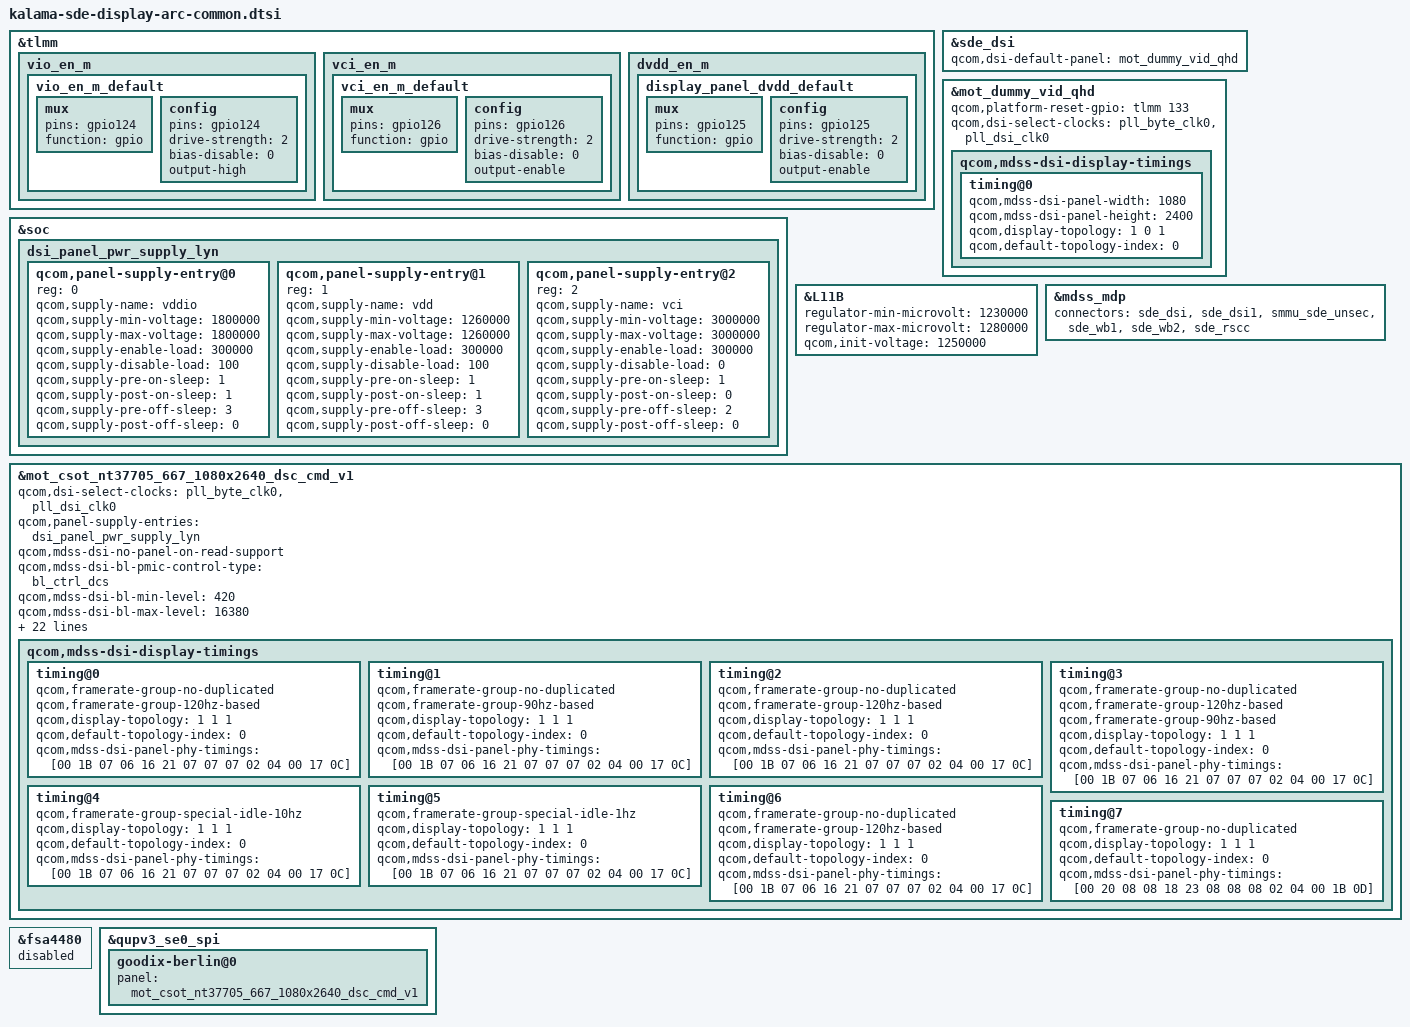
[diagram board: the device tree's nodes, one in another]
/* This is derivated from qcom kalama-sde-display-mtp.dtsi */

#include "kalama-sde-display.dtsi"
#include "dsi-panel-mot-dummy-qhd-video.dtsi"
#include "dsi-panel-mot-csot-nt37705-667-1080x2640-dsc-cmd-common_ly_v1.dtsi"

&tlmm {
	vio_en_m {
		vio_en_m_default: vio_en_m_default {//vio enable 1.8V
			mux {
				pins = "gpio124";
				function = "gpio";
			};

			config {
				pins = "gpio124";
				drive-strength = <2>;   /* 2 mA */
				bias-disable = <0>;   /* no pull */
				output-high;
			};
		};
	};
	vci_en_m {
		vci_en_m_default: vci_en_m_default {//vci enable 3.0V
			mux {
				pins = "gpio126";
				function = "gpio";
			};

			config {
				pins = "gpio126";
				drive-strength = <2>;   /* 2 mA */
				bias-disable = <0>;   /* no pull */
				output-enable;
			};
		};
	};
	dvdd_en_m {
		display_panel_dvdd_default: display_panel_dvdd_default { //dvdd 1.23V
			mux {
				pins = "gpio125";
				function = "gpio";
			};

			config {
				pins = "gpio125";
				drive-strength = <2>;   /* 2 mA */
				bias-disable = <0>;   /* no pull */
				output-enable;
			};
		};
	};
};

&soc {
	dsi_panel_pwr_supply_lyn: dsi_panel_pwr_supply_lyn {
		#address-cells = <1>;
		#size-cells = <0>;

	qcom,panel-supply-entry@0 {
		reg = <0>;
		qcom,supply-name = "vddio";
		qcom,supply-min-voltage = <1800000>;
		qcom,supply-max-voltage = <1800000>;
		qcom,supply-enable-load = <300000>;
		qcom,supply-disable-load = <100>;
		qcom,supply-pre-on-sleep = <1>;
		qcom,supply-post-on-sleep = <1>;
		qcom,supply-pre-off-sleep = <3>;
		qcom,supply-post-off-sleep = <0>;
        };
	qcom,panel-supply-entry@1 {
		reg = <1>;
		qcom,supply-name = "vdd";
		qcom,supply-min-voltage = <1260000>;
		qcom,supply-max-voltage = <1260000>;
		qcom,supply-enable-load = <300000>;
		qcom,supply-disable-load = <100>;
		qcom,supply-pre-on-sleep = <1>;
		qcom,supply-post-on-sleep = <1>;
		qcom,supply-pre-off-sleep = <3>;
		qcom,supply-post-off-sleep = <0>;
        };

        qcom,panel-supply-entry@2 {
		reg = <2>;
		qcom,supply-name = "vci";
		qcom,supply-min-voltage = <3000000>;
		qcom,supply-max-voltage = <3000000>;
		qcom,supply-enable-load = <300000>;
		qcom,supply-disable-load = <0>;
		qcom,supply-pre-on-sleep = <1>;
		qcom,supply-post-on-sleep = <0>;
		qcom,supply-pre-off-sleep = <2>;
		qcom,supply-post-off-sleep = <0>;
        };
	};

};

&sde_dsi {
	qcom,dsi-default-panel = <&mot_dummy_vid_qhd>;
};

&mot_dummy_vid_qhd {
       qcom,mdss-dsi-display-timings {
                timing@0{
                       qcom,mdss-dsi-panel-width = <1080>;
                       qcom,mdss-dsi-panel-height = <2400>;
               };
       };
};

&L11B {
       regulator-min-microvolt = <1230000>;
       regulator-max-microvolt = <1280000>;
       qcom,init-voltage = <1250000>;
};

/*&sde_dsi1 {
	vddio-supply = <&L17B>;
	vci-supply = <&L9C>;
};*/


&mdss_mdp {
	connectors = <&sde_dsi &sde_dsi1 &smmu_sde_unsec &sde_wb1 &sde_wb2 &sde_rscc>;
};

&mot_csot_nt37705_667_1080x2640_dsc_cmd_v1 {
	qcom,dsi-select-clocks = "pll_byte_clk0", "pll_dsi_clk0";
	qcom,panel-supply-entries = <&dsi_panel_pwr_supply_lyn>;
	qcom,mdss-dsi-no-panel-on-read-support;
	qcom,mdss-dsi-bl-pmic-control-type = "bl_ctrl_dcs";
	qcom,mdss-dsi-bl-min-level = <420>;
	qcom,mdss-dsi-bl-max-level = <16380>;
	qcom,mdss-dsi-bl-default-level = <10230>;
	qcom,mdss-brightness-max-level = <16380>;
	qcom,platform-reset-gpio = <&tlmm 133 0>;
	qcom,platform-vio-enable-gpio = <&tlmm 124 0>;
	qcom,platform-vci-enable-gpio = <&tlmm 126 0>;
	qcom,bl-dsc-cmd-state = "dsi_hs_mode";
	qcom,mdss-dsi-bl-inverted-dbv;
	qcom,mdss-dsi-bl-is-exponent;


	qcom,mdss-dsi-panel-status-check-mode = "reg_read";
	qcom,mdss-dsi-panel-status-command = [06 01 00 01 00 00 01 0a];
	qcom,mdss-dsi-panel-status-command-state = "dsi_lp_mode";
	qcom,mdss-dsi-panel-status-value = <0x9c>;
	qcom,mdss-dsi-panel-status-read-length = <1>;
	qcom,esd-check-enabled;
	qcom,cellid-read-enabled;
	qcom,mdss-dsi-panel-cellid-read-length = <36>;
	qcom,mdss-dsi-panel-cellid-offset = <13>;
	qcom,mdss-dsi-panel-cellid-command = [
		06 01 00 01 00 00 01 AC];
	qcom,mdss-dsi-display-timings {
		timing@0 { //120
			qcom,framerate-group-no-duplicated;
			qcom,framerate-group-120hz-based;
			//qcom,mdss-dsi-panel-clockrate = <880000000>;
			qcom,display-topology = <1 1 1>;
			qcom,default-topology-index = <0>;
			qcom,mdss-dsi-panel-phy-timings = [00 1B 07 06 16 21 07
							07 07 02 04 00 17 0C];
		};
		timing@1 { //90
			qcom,framerate-group-no-duplicated;
			qcom,framerate-group-90hz-based;
			//qcom,mdss-dsi-panel-clockrate = <880000000>;
			qcom,display-topology = <1 1 1>;
			qcom,default-topology-index = <0>;
			qcom,mdss-dsi-panel-phy-timings = [00 1B 07 06 16 21 07
							07 07 02 04 00 17 0C];
		};
		timing@2 { //60
			qcom,framerate-group-no-duplicated;
			qcom,framerate-group-120hz-based;
			//qcom,mdss-dsi-panel-clockrate = <880000000>;
			qcom,display-topology = <1 1 1>;
			qcom,default-topology-index = <0>;
			qcom,mdss-dsi-panel-phy-timings = [00 1B 07 06 16 21 07
							07 07 02 04 00 17 0C];
		};
		timing@3 { //30
			qcom,framerate-group-no-duplicated;
			qcom,framerate-group-120hz-based;
			qcom,framerate-group-90hz-based;
			//qcom,mdss-dsi-panel-clockrate = <880000000>;
			qcom,display-topology = <1 1 1>;
			qcom,default-topology-index = <0>;
			qcom,mdss-dsi-panel-phy-timings = [00 1B 07 06 16 21 07
							07 07 02 04 00 17 0C];
		};
		timing@4 { //10 independent
			qcom,framerate-group-special-idle-10hz;
			//qcom,mdss-dsi-panel-clockrate = <880000000>;
			qcom,display-topology = <1 1 1>;
			qcom,default-topology-index = <0>;
			qcom,mdss-dsi-panel-phy-timings = [00 1B 07 06 16 21 07
							07 07 02 04 00 17 0C];
		};
		timing@5 { //1 independent
			qcom,framerate-group-special-idle-1hz;
			//qcom,mdss-dsi-panel-clockrate = <880000000>;
			qcom,display-topology = <1 1 1>;
			qcom,default-topology-index = <0>;
			qcom,mdss-dsi-panel-phy-timings = [00 1B 07 06 16 21 07
							07 07 02 04 00 17 0C];
		};
		timing@6 { //24
			qcom,framerate-group-no-duplicated;
			qcom,framerate-group-120hz-based;
			//qcom,mdss-dsi-panel-clockrate = <880000000>;
			qcom,display-topology = <1 1 1>;
			qcom,default-topology-index = <0>;
			qcom,mdss-dsi-panel-phy-timings = [00 1B 07 06 16 21 07
							07 07 02 04 00 17 0C];
		};
		timing@7 { //144
			qcom,framerate-group-no-duplicated;
			//qcom,mdss-dsi-panel-clockrate = <880000000>;
			qcom,display-topology = <1 1 1>;
			qcom,default-topology-index = <0>;
			qcom,mdss-dsi-panel-phy-timings = [00 20 08 08 18 23 08
							08 08 02 04 00 1B 0D];
		};
	};
};

&mot_dummy_vid_qhd {
	qcom,platform-reset-gpio = <&tlmm 133 0>;

	qcom,dsi-select-clocks = "pll_byte_clk0", "pll_dsi_clk0";
	qcom,mdss-dsi-display-timings {
		timing@0 {
			qcom,display-topology = <1 0 1>;
			qcom,default-topology-index = <0>;
		};
	};
};

&fsa4480 {
	status = "disabled";
};

&qupv3_se0_spi {
	goodix-berlin@0 {
		panel = <&mot_csot_nt37705_667_1080x2640_dsc_cmd_v1>;
	};
};
